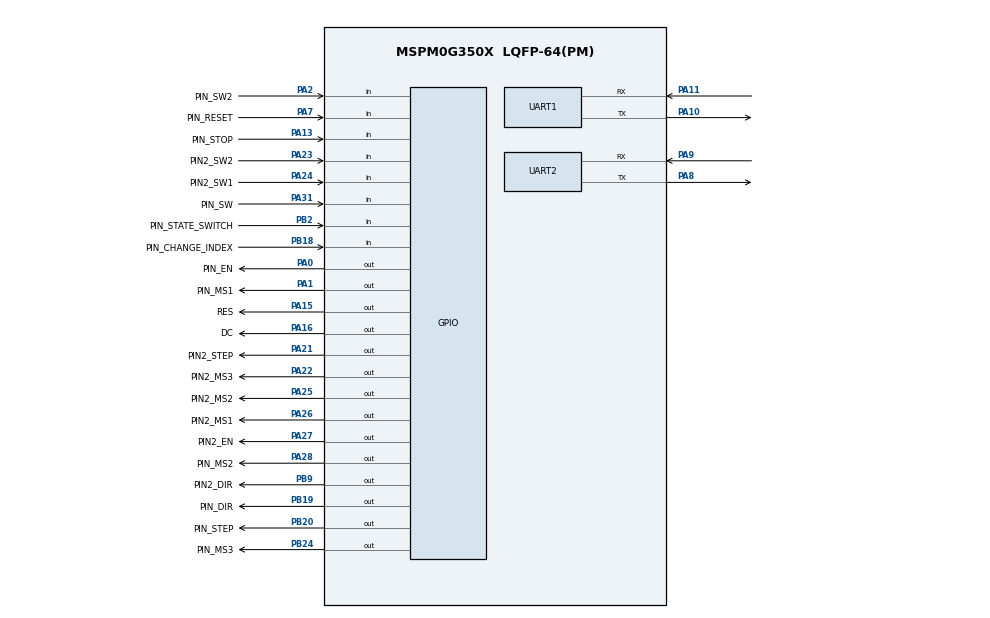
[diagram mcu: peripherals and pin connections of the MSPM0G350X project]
/**
 * @cliArgs --device "MSPM0G350X" --part "Default" --package "LQFP-64(PM)" --product "mspm0_sdk@2.10.00.04"
 * @versions {"tool":"1.27.0+4565"}
 */

/**
 * Import the modules used in this configuration.
 */
const GPIO    = scripting.addModule("/ti/driverlib/GPIO", {}, false);
const GPIO1   = GPIO.addInstance();
const GPIO2   = GPIO.addInstance();
const GPIO3   = GPIO.addInstance();
const GPIO4   = GPIO.addInstance();
const SPI     = scripting.addModule("/ti/driverlib/SPI", {}, false);
const SPI1    = SPI.addInstance();
const SYSCTL  = scripting.addModule("/ti/driverlib/SYSCTL");
const SYSTICK = scripting.addModule("/ti/driverlib/SYSTICK");
const TIMER   = scripting.addModule("/ti/driverlib/TIMER", {}, false);
const TIMER1  = TIMER.addInstance();
const TIMER2  = TIMER.addInstance();
const UART    = scripting.addModule("/ti/driverlib/UART", {}, false);
const UART1   = UART.addInstance();
const UART2   = UART.addInstance();

/**
 * Write custom configuration values to the imported modules.
 */
const gate7  = system.clockTree["MFCLKGATE"];
gate7.enable = true;

GPIO1.$name                              = "GPIO_MOTOR1";
GPIO1.associatedPins.create(8);
GPIO1.associatedPins[0].internalResistor = "PULL_UP";
GPIO1.associatedPins[0].$name            = "PIN_DIR";
GPIO1.associatedPins[0].pin.$assign      = "PB19";
GPIO1.associatedPins[1].$name            = "PIN_MS1";
GPIO1.associatedPins[1].pin.$assign      = "PA1";
GPIO1.associatedPins[2].$name            = "PIN_MS2";
GPIO1.associatedPins[2].pin.$assign      = "PA28";
GPIO1.associatedPins[3].$name            = "PIN_MS3";
GPIO1.associatedPins[3].pin.$assign      = "PB24";
GPIO1.associatedPins[4].$name            = "PIN_SW";
GPIO1.associatedPins[4].direction        = "INPUT";
GPIO1.associatedPins[4].internalResistor = "PULL_UP";
GPIO1.associatedPins[4].pin.$assign      = "PA31";
GPIO1.associatedPins[5].$name            = "PIN_EN";
GPIO1.associatedPins[5].pin.$assign      = "PA0";
GPIO1.associatedPins[6].$name            = "PIN_STEP";
GPIO1.associatedPins[6].pin.$assign      = "PB20";
GPIO1.associatedPins[7].$name            = "PIN_SW2";
GPIO1.associatedPins[7].direction        = "INPUT";
GPIO1.associatedPins[7].internalResistor = "PULL_UP";
GPIO1.associatedPins[7].pin.$assign      = "PA2";

const Board = scripting.addModule("/ti/driverlib/Board", {}, false);

GPIO2.$name                          = "ST7735";
GPIO2.associatedPins.create(4);
GPIO2.associatedPins[0].$name        = "RES";
GPIO2.associatedPins[0].initialValue = "SET";
GPIO2.associatedPins[0].assignedPin  = "15";
GPIO2.associatedPins[0].pin.$assign  = "PA15";
GPIO2.associatedPins[1].$name        = "DC";
GPIO2.associatedPins[1].initialValue = "SET";
GPIO2.associatedPins[1].assignedPin  = "16";
GPIO2.associatedPins[1].pin.$assign  = "PA16";
GPIO2.associatedPins[2].$name        = "CS";
GPIO2.associatedPins[2].initialValue = "SET";
GPIO2.associatedPins[2].assignedPin  = "17";
GPIO2.associatedPins[3].$name        = "BL";
GPIO2.associatedPins[3].initialValue = "SET";
GPIO2.associatedPins[3].assignedPin  = "18";

GPIO3.$name                              = "GPIO_MOTOR2";
GPIO3.associatedPins.create(8);
GPIO3.associatedPins[0].$name            = "PIN2_DIR";
GPIO3.associatedPins[0].pin.$assign      = "PB9";
GPIO3.associatedPins[1].$name            = "PIN2_MS1";
GPIO3.associatedPins[1].pin.$assign      = "PA26";
GPIO3.associatedPins[2].$name            = "PIN2_MS2";
GPIO3.associatedPins[2].pin.$assign      = "PA25";
GPIO3.associatedPins[3].$name            = "PIN2_MS3";
GPIO3.associatedPins[3].pin.$assign      = "PA22";
GPIO3.associatedPins[4].$name            = "PIN2_EN";
GPIO3.associatedPins[4].pin.$assign      = "PA27";
GPIO3.associatedPins[5].$name            = "PIN2_STEP";
GPIO3.associatedPins[5].pin.$assign      = "PA21";
GPIO3.associatedPins[6].$name            = "PIN2_SW1";
GPIO3.associatedPins[6].direction        = "INPUT";
GPIO3.associatedPins[6].internalResistor = "PULL_UP";
GPIO3.associatedPins[6].pin.$assign      = "PA24";
GPIO3.associatedPins[7].$name            = "PIN2_SW2";
GPIO3.associatedPins[7].direction        = "INPUT";
GPIO3.associatedPins[7].internalResistor = "PULL_UP";
GPIO3.associatedPins[7].pin.$assign      = "PA23";

GPIO4.$name                              = "GPIO_CONTROL";
GPIO4.associatedPins.create(4);
GPIO4.associatedPins[0].direction        = "INPUT";
GPIO4.associatedPins[0].internalResistor = "PULL_UP";
GPIO4.associatedPins[0].$name            = "PIN_CHANGE_INDEX";
GPIO4.associatedPins[0].pin.$assign      = "PB18";
GPIO4.associatedPins[1].direction        = "INPUT";
GPIO4.associatedPins[1].internalResistor = "PULL_UP";
GPIO4.associatedPins[1].$name            = "PIN_STATE_SWITCH";
GPIO4.associatedPins[1].pin.$assign      = "PB2";
GPIO4.associatedPins[2].$name            = "PIN_RESET";
GPIO4.associatedPins[2].direction        = "INPUT";
GPIO4.associatedPins[2].internalResistor = "PULL_UP";
GPIO4.associatedPins[2].pin.$assign      = "PA7";
GPIO4.associatedPins[3].$name            = "PIN_STOP";
GPIO4.associatedPins[3].direction        = "INPUT";
GPIO4.associatedPins[3].internalResistor = "PULL_UP";
GPIO4.associatedPins[3].pin.$assign      = "PA13";

SPI1.$name                              = "ST7735_SPI";
SPI1.frameFormat                        = "MOTO3";
SPI1.direction                          = "PICO";
SPI1.sclkPinConfig.$name                = "ti_driverlib_gpio_GPIOPinGeneric0";
SPI1.sclkPinConfig.direction            = scripting.forceWrite("OUTPUT");
SPI1.sclkPinConfig.onlyInternalResistor = scripting.forceWrite(false);
SPI1.sclkPinConfig.passedPeripheralType = scripting.forceWrite("Digital");
SPI1.mosiPinConfig.direction            = scripting.forceWrite("OUTPUT");
SPI1.mosiPinConfig.hideOutputInversion  = scripting.forceWrite(false);
SPI1.mosiPinConfig.onlyInternalResistor = scripting.forceWrite(false);
SPI1.mosiPinConfig.passedPeripheralType = scripting.forceWrite("Digital");
SPI1.mosiPinConfig.$name                = "ti_driverlib_gpio_GPIOPinGeneric5";

SYSCTL.forceDefaultClkConfig = true;
SYSCTL.clockTreeEn           = true;

SYSTICK.interruptEnable   = true;
SYSTICK.systickEnable     = true;
SYSTICK.periodEnable      = true;
SYSTICK.period            = 40000;
SYSTICK.interruptPriority = "2";

TIMER1.timerPeriod        = "1 ms";
TIMER1.interrupts         = ["ZERO"];
TIMER1.timerMode          = "PERIODIC";
TIMER1.$name              = "TIMER_1";
TIMER1.peripheral.$assign = "TIMG12";

TIMER2.$name              = "TIMER_2";
TIMER2.timerPeriod        = "1 ms";
TIMER2.timerMode          = "PERIODIC";
TIMER2.interrupts         = ["ZERO"];
TIMER2.peripheral.$assign = "TIMG6";

UART1.$name                    = "UART_0";
UART1.enabledInterrupts        = ["RX"];
UART1.uartClkSrc               = "MFCLK";
UART1.targetBaudRate           = 115200;
UART1.peripheral.rxPin.$assign = "PA11";
UART1.peripheral.txPin.$assign = "PA10";
UART1.txPinConfig.$name        = "ti_driverlib_gpio_GPIOPinGeneric1";
UART1.rxPinConfig.$name        = "ti_driverlib_gpio_GPIOPinGeneric2";

UART2.$name                    = "UART_1";
UART2.targetBaudRate           = 115200;
UART2.uartClkSrc               = "MFCLK";
UART2.interruptPriority        = "0";
UART2.enabledInterrupts        = ["RX"];
UART2.peripheral.rxPin.$assign = "PA9";
UART2.peripheral.txPin.$assign = "PA8";
UART2.txPinConfig.$name        = "ti_driverlib_gpio_GPIOPinGeneric3";
UART2.rxPinConfig.$name        = "ti_driverlib_gpio_GPIOPinGeneric4";

/**
 * Pinmux solution for unlocked pins/peripherals. This ensures that minor changes to the automatic solver in a future
 * version of the tool will not impact the pinmux you originally saw.  These lines can be completely deleted in order to
 * re-solve from scratch.
 */
Board.peripheral.$suggestSolution            = "DEBUGSS";
Board.peripheral.swclkPin.$suggestSolution   = "PA20";
Board.peripheral.swdioPin.$suggestSolution   = "PA19";
GPIO2.associatedPins[2].pin.$suggestSolution = "PA17";
GPIO2.associatedPins[3].pin.$suggestSolution = "PA18";
SPI1.peripheral.$suggestSolution             = "SPI0";
SPI1.peripheral.sclkPin.$suggestSolution     = "PA12";
SPI1.peripheral.mosiPin.$suggestSolution     = "PA14";
UART1.peripheral.$suggestSolution            = "UART0";
UART2.peripheral.$suggestSolution            = "UART1";
